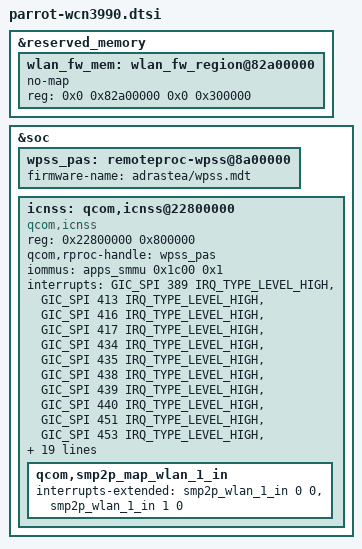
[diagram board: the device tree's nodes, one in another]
#include "parrot.dtsi"

&reserved_memory {
	wlan_fw_mem: wlan_fw_region@82a00000 {
		no-map;
		reg = <0x0 0x82a00000 0x0 0x300000>;
	};
};

&soc {
	wpss_pas: remoteproc-wpss@8a00000 {
		firmware-name = "adrastea/wpss.mdt";
	};

	icnss: qcom,icnss@22800000 {
		compatible = "qcom,icnss";
		reg = <0x22800000 0x800000>;
		reg-names = "membase";
		qcom,rproc-handle = <&wpss_pas>;
		iommus = <&apps_smmu 0x1c00 0x1>;
		interrupts = <GIC_SPI 389 IRQ_TYPE_LEVEL_HIGH /* CE0 */ >,
			     <GIC_SPI 413 IRQ_TYPE_LEVEL_HIGH /* CE1 */ >,
			     <GIC_SPI 416 IRQ_TYPE_LEVEL_HIGH /* CE2 */ >,
			     <GIC_SPI 417 IRQ_TYPE_LEVEL_HIGH /* CE3 */ >,
			     <GIC_SPI 434 IRQ_TYPE_LEVEL_HIGH /* CE4 */ >,
			     <GIC_SPI 435 IRQ_TYPE_LEVEL_HIGH /* CE5 */ >,
			     <GIC_SPI 438 IRQ_TYPE_LEVEL_HIGH /* CE6 */ >,
			     <GIC_SPI 439 IRQ_TYPE_LEVEL_HIGH /* CE7 */ >,
			     <GIC_SPI 440 IRQ_TYPE_LEVEL_HIGH /* CE8 */ >,
			     <GIC_SPI 451 IRQ_TYPE_LEVEL_HIGH /* CE9 */ >,
			     <GIC_SPI 453 IRQ_TYPE_LEVEL_HIGH /* CE10 */ >,
			     <GIC_SPI 454 IRQ_TYPE_LEVEL_HIGH /* CE11 */ >;
		qcom,iommu-dma = "fastmap";
		qcom,iommu-faults = "stall-disable", "HUPCF", "non-fatal";
		qcom,iommu-dma-addr-pool = <0xa0000000 0x10000000>;
		qcom,fw-prefix;
		qcom,wlan;
		bdf-download-support;
		wpss-support-enable;
		qcom,wlan-msa-fixed-region = <&wlan_fw_mem>;
		vdd-cx-mx-supply = <&L11B>;
		vdd-1.8-xo-supply = <&L1E>;
		vdd-1.3-rfa-supply = <&L14B>;
		vdd-3.3-ch1-supply = <&L11E>;
		vdd-3.3-ch0-supply = <&L10E>;
		qcom,vdd-cx-mx-config = <640000 640000>;
		qcom,vdd-3.3-ch1-config = <3000000 3312000>;
		qcom,vdd-3.3-ch0-config = <3000000 3312000>;
		qcom,smp2p_map_wlan_1_in {
			interrupts-extended = <&smp2p_wlan_1_in 0 0>,
					      <&smp2p_wlan_1_in 1 0>;
			interrupt-names = "qcom,smp2p-force-fatal-error",
					  "qcom,smp2p-early-crash-ind";
		};

	};
};
